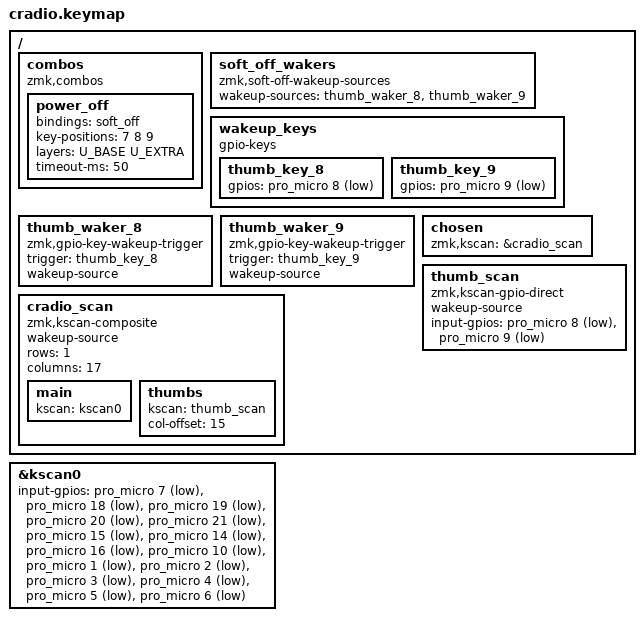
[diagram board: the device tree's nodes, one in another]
// Copyright 2021 Manna Harbour
// https://github.com/manna-harbour/miryoku

#include "../miryoku/custom_config.h"
#include "../miryoku/mapping/34/ferris.h"
#include "../miryoku/miryoku.dtsi"

&kscan0 {
    /delete-property/ wakeup-source;
    input-gpios
        = <&pro_micro 7 (GPIO_ACTIVE_LOW | GPIO_PULL_UP)>
        , <&pro_micro 18 (GPIO_ACTIVE_LOW | GPIO_PULL_UP)>
        , <&pro_micro 19 (GPIO_ACTIVE_LOW | GPIO_PULL_UP)>
        , <&pro_micro 20 (GPIO_ACTIVE_LOW | GPIO_PULL_UP)>
        , <&pro_micro 21 (GPIO_ACTIVE_LOW | GPIO_PULL_UP)>
        , <&pro_micro 15 (GPIO_ACTIVE_LOW | GPIO_PULL_UP)>
        , <&pro_micro 14 (GPIO_ACTIVE_LOW | GPIO_PULL_UP)>
        , <&pro_micro 16 (GPIO_ACTIVE_LOW | GPIO_PULL_UP)>
        , <&pro_micro 10 (GPIO_ACTIVE_LOW | GPIO_PULL_UP)>
        , <&pro_micro 1 (GPIO_ACTIVE_LOW | GPIO_PULL_UP)>
        , <&pro_micro 2 (GPIO_ACTIVE_LOW | GPIO_PULL_UP)>
        , <&pro_micro 3 (GPIO_ACTIVE_LOW | GPIO_PULL_UP)>
        , <&pro_micro 4 (GPIO_ACTIVE_LOW | GPIO_PULL_UP)>
        , <&pro_micro 5 (GPIO_ACTIVE_LOW | GPIO_PULL_UP)>
        , <&pro_micro 6 (GPIO_ACTIVE_LOW | GPIO_PULL_UP)>
        ;
};

/ {
    combos {
        compatible = "zmk,combos";

        power_off {
            bindings = <&soft_off>;
            key-positions = <7 8 9>;
            layers = <U_BASE U_EXTRA>;
            timeout-ms = <50>;
        };
    };

    soft_off_wakers {
        compatible = "zmk,soft-off-wakeup-sources";
        wakeup-sources = <&thumb_waker_8 &thumb_waker_9>;
    };

    wakeup_keys {
        compatible = "gpio-keys";

        thumb_key_8: thumb_key_8 {
            gpios = <&pro_micro 8 (GPIO_ACTIVE_LOW | GPIO_PULL_UP)>;
        };

        thumb_key_9: thumb_key_9 {
            gpios = <&pro_micro 9 (GPIO_ACTIVE_LOW | GPIO_PULL_UP)>;
        };
    };

    thumb_waker_8: thumb_waker_8 {
        compatible = "zmk,gpio-key-wakeup-trigger";
        trigger = <&thumb_key_8>;
        wakeup-source;
    };

    thumb_waker_9: thumb_waker_9 {
        compatible = "zmk,gpio-key-wakeup-trigger";
        trigger = <&thumb_key_9>;
        wakeup-source;
    };

    chosen {
        zmk,kscan = &cradio_scan;
    };

    thumb_scan: thumb_scan {
        compatible = "zmk,kscan-gpio-direct";
        wakeup-source;
        input-gpios = <&pro_micro 8 (GPIO_ACTIVE_LOW | GPIO_PULL_UP)>,
                      <&pro_micro 9 (GPIO_ACTIVE_LOW | GPIO_PULL_UP)>;
    };

    cradio_scan: cradio_scan {
        compatible = "zmk,kscan-composite";
        wakeup-source;
        rows = <1>;
        columns = <17>;

        main {
            kscan = <&kscan0>;
        };

        thumbs {
            kscan = <&thumb_scan>;
            col-offset = <15>;
        };
    };
};
